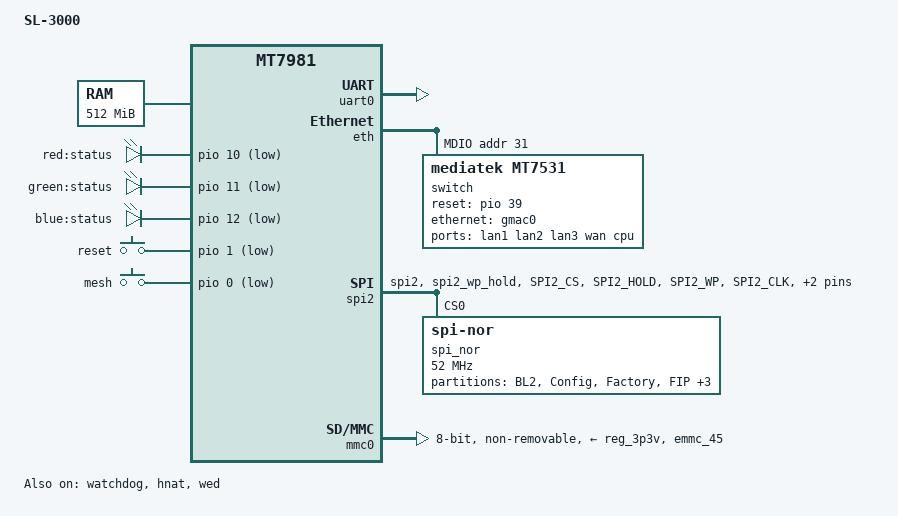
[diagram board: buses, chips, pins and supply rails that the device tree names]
/dts-v1/;
#include "mt7981.dtsi"

/ {
	model = "SL-3000";
	compatible = "sl,3000", "mediatek,mt7981";

	chosen {
		bootargs = "console=ttyS0,115200n1 loglevel=8 \
			    earlycon=uart8250,mmio32,0x11002000 \
			    root=PARTLABEL=rootfs rootwait rootfstype=squashfs,f2fs";
	};

	aliases {
		led-boot = &status_red_led;
		led-failsafe = &status_red_led;
		led-running = &status_green_led;
		led-upgrade = &status_blue_led;
	};

	memory {
		reg = <0 0x40000000 0 0x20000000>;
	};

        leds {
                compatible = "gpio-leds";

                status_red_led: led-0 {
                        label = "red:status";
                        gpios = <&pio 10 GPIO_ACTIVE_LOW>;
                };

                status_green_led: led-1 {
                        label = "green:status";
                        gpios = <&pio 11 GPIO_ACTIVE_LOW>;
                };

                status_blue_led: led-2 {
                        label = "blue:status";
                        gpios = <&pio 12 GPIO_ACTIVE_LOW>;
		};
	};

	gpio-keys {
		compatible = "gpio-keys";
		reset {
			label = "reset";
			linux,code = <KEY_RESTART>;
			gpios = <&pio 1 GPIO_ACTIVE_LOW>;
		};

		mesh {
			label = "mesh";
			gpios = <&pio 0 GPIO_ACTIVE_LOW>;
			linux,code = <BTN_9>;
			linux,input-type = <EV_SW>;
		};
	};
};

&uart0 {
	status = "okay";
};

&watchdog {
	status = "okay";
};

&eth {
	status = "okay";

	gmac0: mac@0 {
		compatible = "mediatek,eth-mac";
		reg = <0>;
		phy-mode = "2500base-x";

		fixed-link {
			speed = <2500>;
			full-duplex;
			pause;
		};
	};
	
	gmac1: mac@1 {
		compatible = "mediatek,eth-mac";
		reg = <1>;
		phy-mode = "2500base-x";

		fixed-link {
			speed = <2500>;
			full-duplex;
			pause;
		};
	};



	mdio: mdio-bus {
		#address-cells = <1>;
		#size-cells = <0>;


		switch@0 {
			compatible = "mediatek,mt7531";
			reg = <31>;
			reset-gpios = <&pio 39 0>;

			ports {
				#address-cells = <1>;
				#size-cells = <0>;

				port@0 {
					reg = <0>;
					label = "lan1";
				};

				port@1 {
					reg = <1>;
					label = "lan2";
				};

				port@2 {
					reg = <2>;
					label = "lan3";
				};

				port@3 {
					reg = <3>;
					label = "wan";
				};
				
				port@6 {
					reg = <6>;
					label = "cpu";
					ethernet = <&gmac0>;
					phy-mode = "2500base-x";

					fixed-link {
						speed = <2500>;
						full-duplex;
						pause;
					};
				};
			};
		};
	};
};

&hnat {
	mtketh-wan = "eth1";
	mtketh-lan = "lan";
	mtketh-ppd = "eth1";
	mtketh-max-gmac = <2>;
	status = "okay";
};

&spi1 {
	pinctrl-names = "default";
	pinctrl-0 = <&spic_pins>;
	status = "disabled";
};

&spi2 {
	pinctrl-names = "default";
	pinctrl-0 = <&spi2_flash_pins>;
	status = "okay";
	spi_nor@0 {
		#address-cells = <1>;
		#size-cells = <1>;
		compatible = "jedec,spi-nor";
		spi-cal-enable;
		spi-cal-mode = "read-data";
		spi-cal-datalen = <7>;
		spi-cal-data = /bits/ 8 <
			0x53 0x46 0x5F 0x42 0x4F 0x4F 0x54>; /* SF_BOOT */
		spi-cal-addrlen = <1>;
		spi-cal-addr = /bits/ 32 <0x0>;
		reg = <0>;
		spi-max-frequency = <52000000>;
		spi-tx-bus-width = <4>;
		spi-rx-bus-width = <4>;

		partition@00000 {
			label = "BL2";
			reg = <0x00000 0x0100000>;
		};
		partition@100000 {
			label = "Config";
			reg = <0x100000 0x080000>;
		};
		partition@180000 {
			label = "Factory";
			reg = <0x180000 0x0200000>;
		};
		partition@380000 {
			label = "FIP";
			reg = <0x380000 0x0200000>;
		};
		partition@580000 {
			label = "firmware";
			reg = <0x580000 0x1900000>;
		};
		partition@1E80000 {
			label = "Product";
			reg = <0x1E80000 0x20000>;
		};
		partition@1EA0000 {
			label = "Custom";
			reg = <0x1EA0000 0x160000>;
		};
	};
};

&mmc0 {
	bus-width = <8>;
	cap-mmc-highspeed;
	max-frequency = <52000000>;
	no-sd;
	no-sdio;
	non-removable;
	pinctrl-names = "default", "state_uhs";
	pinctrl-0 = <&mmc0_pins_default>;
	pinctrl-1 = <&mmc0_pins_uhs>;
	vmmc-supply = <&reg_3p3v>;
	non-removable;
	status = "okay";
};

&pio {
	spic_pins: spi1-pins {
		mux {
			function = "spi";
			groups = "spi1_1";
		};
	};

	spi2_flash_pins: spi2-pins {
		mux {
			function = "spi";
			groups = "spi2", "spi2_wp_hold";
		};

		conf-pu {
			pins = "SPI2_CS", "SPI2_HOLD", "SPI2_WP";
			drive-strength = <MTK_DRIVE_8mA>;
			bias-pull-up = <MTK_PUPD_SET_R1R0_11>;
		};

		conf-pd {
			pins = "SPI2_CLK", "SPI2_MOSI", "SPI2_MISO";
			drive-strength = <MTK_DRIVE_8mA>;
			bias-pull-down = <MTK_PUPD_SET_R1R0_11>;
		};
	};
	
	mmc0_pins_default: mmc0-pins-default {
		mux {
			function = "flash";
			groups = "emmc_45";
		};
	};

	mmc0_pins_uhs: mmc0-pins-uhs {
		mux {
			function = "flash";
			groups = "emmc_45";
		};
	};
};

&wed {
	dy_txbm_enable = "true";
	dy_txbm_budget = <8>;
	txbm_init_sz = <8>;
	txbm_max_sz = <32>;
	status = "okay";
};
